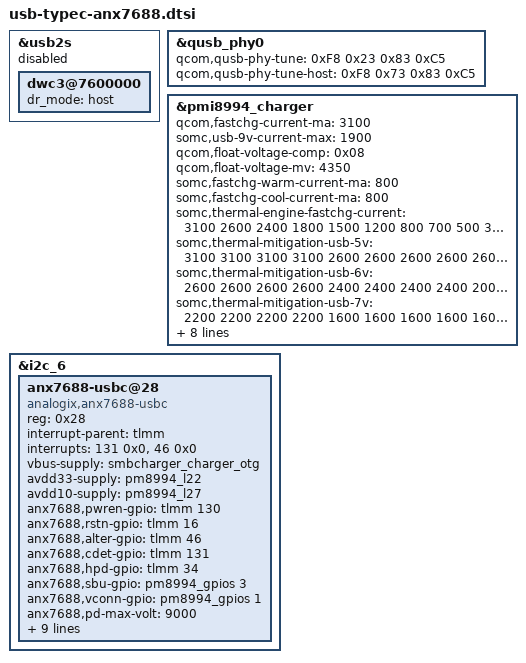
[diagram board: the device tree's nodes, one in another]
/* Copyright (c) 2015, The Linux Foundation. All rights reserved.
 *
 * This program is free software; you can redistribute it and/or modify
 * it under the terms of the GNU General Public License version 2 and
 * only version 2 as published by the Free Software Foundation.
 *
 * This program is distributed in the hope that it will be useful,
 * but WITHOUT ANY WARRANTY; without even the implied warranty of
 * MERCHANTABILITY or FITNESS FOR A PARTICULAR PURPOSE.  See the
 * GNU General Public License for more details.
 */

/* From usb dtsi - same */
&usb2s {
	status = "disabled";

	dwc3@7600000 {
		dr_mode = "host";
	};
};

/* From usb dtsi - same tuning */
&qusb_phy0 {
	qcom,qusb-phy-tune = <0xF8 0x23 0x83 0xC5>;
	qcom,qusb-phy-tune-host = <0xF8 0x73 0x83 0xC5>;
};

&pmi8994_charger {
		qcom,fastchg-current-ma = <3100>;
		somc,usb-9v-current-max = <1900>;
		qcom,float-voltage-comp = <0x08>;
		qcom,float-voltage-mv = <4350>;
		somc,fastchg-warm-current-ma = <800>;
		somc,fastchg-cool-current-ma = <800>;
		somc,thermal-engine-fastchg-current = <3100 2600 2400 1800 1500 1200 800 700 500 300 300 300 300 0 0>;
		somc,thermal-mitigation-usb-5v = <3100 3100 3100 3100 2600 2600 2600 2600 2600 2400 1200 800 300 0 0>;
		somc,thermal-mitigation-usb-6v = <2600 2600 2600 2600 2400 2400 2400 2400 2000 1500 900 500 300 0 0>;
		somc,thermal-mitigation-usb-7v = <2200 2200 2200 2200 1600 1600 1600 1600 1600 1200 900 500 300 0 0>;
		somc,thermal-mitigation-usb-8v = <1900 1900 1900 1900 1400 1400 1400 1400 1200 900 700 500 300 0 0>;
		somc,thermal-mitigation-usb-9v = <1900 1900 1900 1900 1400 1400 1400 1400 1000 800 700 500 300 0 0>;
		somc,limit-usb-5v-level = <8>;
		qcom,external-typec;
		qcom,typec-psy-name = "usb_pd";
		somc,typec-current-max = <3300>;
};

&i2c_6 {
	anx7688-usbc@28 {
		compatible = "analogix,anx7688-usbc";
		reg = <0x28>;

		status = "ok";

		interrupt-parent = <&tlmm>;
		interrupts = <131 0x0>, <46 0x0>;

		vbus-supply = <&smbcharger_charger_otg>;
		avdd33-supply = <&pm8994_l22>;
		avdd10-supply = <&pm8994_l27>;

		anx7688,pwren-gpio = <&tlmm 130 0x0>;
		anx7688,rstn-gpio = <&tlmm 16 0x0>;
		anx7688,alter-gpio = <&tlmm 46 0>;
		anx7688,cdet-gpio = <&tlmm 131 0x0>;
		anx7688,hpd-gpio = <&tlmm 34 0x0>;
		anx7688,sbu-gpio = <&pm8994_gpios 3 0>;
		anx7688,vconn-gpio = <&pm8994_gpios 1 0>;

		anx7688,pd-max-volt = <9000>;
		anx7688,pd-max-power = <27000>;
		anx7688,pd-min-power = <3000>;

		/* 0: 0V
		 * 1: 1.8V
		 * 2: 2.7V
		 * 3: 3.6V
		 */
		anx7688,vsafe0v-level = <3>;
		anx7688,auto-pd-support;

		qcom,hdmi-tx-map = <&mdss_hdmi_tx>;

		pinctrl-names = "default", "sleep";
		pinctrl-0	= <&anx7688_cable_det_active &anx7688_alt_active>;
		pinctrl-1	= <&anx7688_cable_det_sleep &anx7688_alt_sleep>;
	};
};
